# TLE987x register map
Vendor: Infineon; File version: 3.8
CPU: CM3 r0p0, little endian, no MPU, no FPU, 4 interrupt priority bits
Registers are 32-bit, read-write, reset 0x0 unless marked. A register's access mark holds for its fields unless they carry their own. Offsets are from the block's base; [hi:lo] are bit positions; 'fields as' and 'values as' point back to an identical list.

## MF — Measurement Function
Base 0x48018000
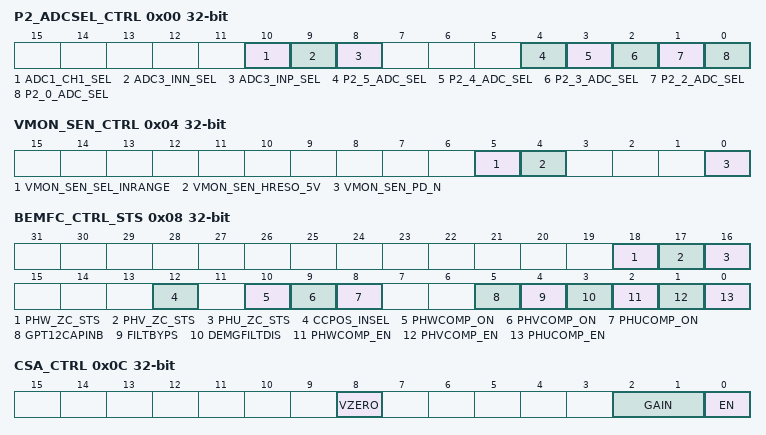
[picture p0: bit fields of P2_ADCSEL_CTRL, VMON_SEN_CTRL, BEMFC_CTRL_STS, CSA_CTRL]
0x00 P2_ADCSEL_CTRL — Port 2 ADC Selection Control Register
  [10] ADC1_CH1_SEL — ADC1 Channel 1 Input Selection
    0=none (Current Sense Amplifier disconnected from ADC1.Ch1); 1=CS_AMP (Current Sense Amplifier is connected to ADC1.Ch1)
  [9] ADC3_INN_SEL — ADC3 Negative Input Selection
    0=none (ADC3.N input disconnected); 1=Mux-Port 2.2 (Port 2.2 multiplexer is connected to ADC2.N)
  [8] ADC3_INP_SEL — ADC3 Positive Input Selection
    0=none (ADC3.P input disconnected); 1=Mux-Port 2.0 (Port 2.0 multiplexer is connected to ADC3.P)
  [4] P2_5_ADC_SEL — Port 2.5 Input Selection
    0=ADC10B (Port 2.5 is connected to Channel 5 of ADC10B); 1=ADC4
  [3] P2_4_ADC_SEL — Port 2.4 Input Selection
    0=ADC10B (Port 2.4 is connected to Channel 4 of ADC10B); 1=ADC4
  [2] P2_3_ADC_SEL — Port 2.3 Input Selection
    0=ADC1.Ch3 (Port 2.3 is connected to ADC1.Ch3); 1=none (ADC1.Ch3 disconnected from P2.3)
  [1] P2_2_ADC_SEL — Port 2.2 Input Selection
    0=ADC10B (Port 2.2 is connected to Channel 2 of ADC10B); 1=ADC3 (Port 2.2 is connected to IN_N of ADC3)
  [0] P2_0_ADC_SEL — Port 2.0 Input Selection
    0=ADC10B (Port 2.0 is connected to Channel 0 of ADC10B); 1=ADC3 (Port 2.0 is connected to IN_P of ADC3)
0x04 VMON_SEN_CTRL — Supply Sense Control Register
  [5] VMON_SEN_SEL_INRANGE — Monitoring Input Attenuator Select Inputrange
    0=range0 (0-18V range is selected); 1=range1 (0-28V range is selected)
  [4] VMON_SEN_HRESO_5V — Monitoring Input Attenuator High Impedance Output Control
    0=High_Resistive_Output_Disable (Connection to ADC input low ohmic); 1=High_Resistive_Output_Enable (Connection to ADC input high ohmic)
  [0] VMON_SEN_PD_N — Monitoring Input Attenuator enable
    0=DISABLE (Attenuator switched off); 1=ENABLE (Attenuator switched on)
0x08 BEMFC_CTRL_STS access per field — BEMF Comparator Control Status Register
  [18] PHW_ZC_STS ro — Phase W Comparator zero crossing status
    0=Below_Threshold (zero crossing comparator input is below threshold); 1=Above_Threshold (zero crossing comparator input is above threshold)
  [17] PHV_ZC_STS ro — Phase V Comparator zero crossing status
    values as PHW_ZC_STS
  [16] PHU_ZC_STS ro — Phase U Comparator zero crossing status
    values as PHW_ZC_STS
  [12] CCPOS_INSEL rw — CCPOSx_3 INSEL select, x = 0,1,2
    0=GPIO (GPIO selected); 1=BEMF (BEMF selected)
  [10] PHWCOMP_ON rw — Phase W Comparator on
    0=DISABLE (Comparator is switched off); 1=ENABLE (Comparator is switched on)
  [9] PHVCOMP_ON rw — Phase V Comparator on
    values as PHWCOMP_ON
  [8] PHUCOMP_ON rw — Phase U Comparator on
    values as PHWCOMP_ON
  [5] GPT12CAPINB rw — GPT12 CAPINB Value
    0=GPIO (CAPINB Input of GPT12 is connected to P0.3); 1=BEMF (CAPINB Input of GPT12 is connected to internal BEMF Comparator Output)
  [4] FILTBYPS rw — BEMF Comparator Output Filter Bypass
    0=ENABLED (BEMF Comparator Output Filter enabled); 1=DISABLED (BEMF Comparator Output Filter disabled)
  [3] DEMGFILTDIS rw — BEMF Comparator Demagnetisation (Demag) Filter Disable
    0=ENABLED (BEMF Comparator Demag Filter enabled); 1=DISABLED (BEMF Comparator Demag Filter disabled)
  [2] PHWCOMP_EN rw — Phase W Comparator enable
    0=DISABLE (Comparator is disabled); 1=ENABLE (Comparator is enabled)
  [1] PHVCOMP_EN rw — Phase V Comparator enable
    values as PHWCOMP_EN
  [0] PHUCOMP_EN rw — Phase U Comparator enable
    values as PHWCOMP_EN
0x0C CSA_CTRL — Current Sense Amplifier Control Register
  [8] VZERO — Current Sense Output Voltage Level to Ground
    0=VOUT (Output Voltage is VOUT of Amplifier); 1=GROUND (Output Voltage is Ground of Feedback Network)
  [2:1] GAIN — OPA gain setting
    0=Gain_10; 1=Gain_20; 2=Gain_40; 3=Gain_60
  [0] EN — OPA enable
    0=DISABLE (OPA switched off); 1=ENABLE (OPA switched on)
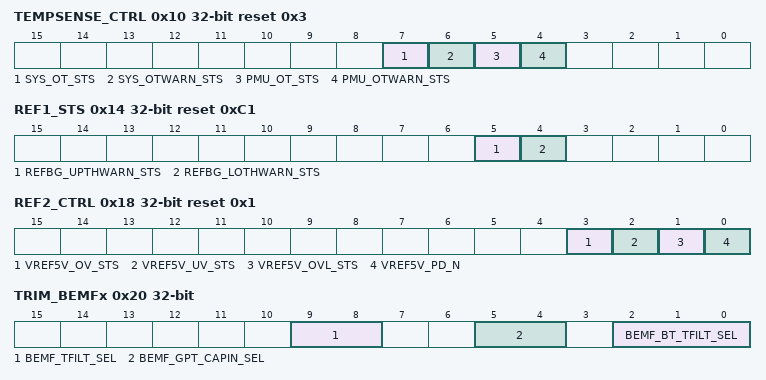
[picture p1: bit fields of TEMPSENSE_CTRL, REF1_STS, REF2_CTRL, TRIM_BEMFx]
0x10 TEMPSENSE_CTRL ro reset 0x3 — Temperature Sensor Control Register
  [all] fields
    0=INACTIVE (write clears status); 1=ACTIVE (interrupt status set)
  [7] SYS_OT_STS — System Overtemperature (MU) Status
  [6] SYS_OTWARN_STS — System Overtemperature Warning (MU) Status
  [5] PMU_OT_STS — PMU Regulator Overtemperature (MU) Status
  [4] PMU_OTWARN_STS — PMU Regulator Overtemperature Warning (MU) Status
0x14 REF1_STS ro reset 0xC1 — Reference 1 Status Register
  [5] REFBG_UPTHWARN_STS — Status for Overvoltage Threshold Measurement of internal VAREF
    0=UPPER_TRIG_RESET (write clears status); 1=UPPER_TRIG_SET (trigger status set)
  [4] REFBG_LOTHWARN_STS — Status for Undervoltage Threshold Measurement of internal VAREF
    values as REFBG_UPTHWARN_STS
0x18 REF2_CTRL access per field reset 0x1 — Reference 2 Control Register
  [3] VREF5V_OV_STS ro — ADC1 Bit Reference Voltage Generation Overvoltage Bit
    0=no Overvoltage detected; 1=Overvoltage detected
  [2] VREF5V_UV_STS ro — ADC1 Bit Reference Voltage Generation Undervoltage Bit
    0=no Undervoltage detected; 1=Undervoltage detected
  [1] VREF5V_OVL_STS ro — ADC1 Bit Reference Voltage Generation Over Load Bit
    0=no OVERLOAD detected; 1=OVERLOAD (OVERLOAD detected)
  [0] VREF5V_PD_N rw — ADC1 Bit Reference Voltage Generation Power Down Bit
    0=DISABLED (Power Down); 1=ACTIVE (no Power Down)
0x20 TRIM_BEMFx — Trimming of Driver
  [9:8] BEMF_TFILT_SEL — Filter Time for BEMF Comparator Output Signal
    0=1 us filter time; 1=2 us filter time; 2=4 us filter time; 3=8 us filter time
  [5:4] BEMF_GPT_CAPIN_SEL — GPT12 CAPIN input selector
    0=SWTRIG (software trigger); 1=Phase_U (trigger from Phase U); 2=Phase_V (trigger from Phase V); 3=Phase_W (trigger from Phase W)
  [2:0] BEMF_BT_TFILT_SEL — Blanking Time for BEMF Comparator Output Signal
    0=6 us filter time; 1=8 us filter time; 2=12 us filter time; 3=16 us filter time; 5=3 us filter time
